# PIC18F27Q10 register map
Vendor: Microchip
Registers are 8-bit, read-write, reset 0x0 unless marked. A register's access mark holds for its fields unless they carry their own. Addresses are absolute, and some are shared; only a register's first bit layout is shown; [hi:lo] are bit positions; {n}, {i} and the like mark numbered series; 'fields as' and 'values as' point back to an identical list.

## wdt_windowed
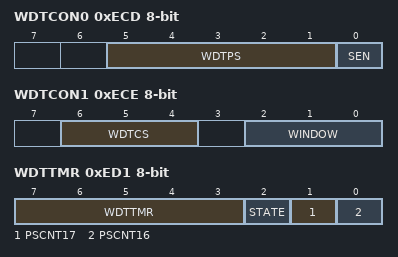
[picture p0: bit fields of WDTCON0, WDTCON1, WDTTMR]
0xECD WDTCON0 reset not defined — (power-on value --qqqqq0)
  [5:1] WDTPS, [0] SEN
0xECE WDTCON1 reset not defined — (power-on value -qqq-qqq)
  [6:4] WDTCS, [2:0] WINDOW
0xECF WDTPSL ro
  [7:0] PSCNT
0xED0 WDTPSH ro
  [7:0] PSCNT
0xED1 WDTTMR ro reset not defined — (power-on value xxxxx000)
  [7:3] WDTTMR, [2] STATE, [1] PSCNT17, [0] PSCNT16

## DOS_02264_pmd_mid8_v1_KFAE
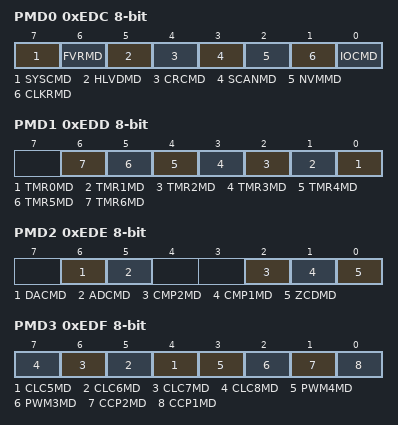
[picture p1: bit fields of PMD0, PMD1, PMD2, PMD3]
0xEDC PMD0 reset not defined — (power-on value 00x00000)
  [7] SYSCMD, [6] FVRMD, [5] HLVDMD, [4] CRCMD, [3] SCANMD, [2] NVMMD, [1] CLKRMD, [0] IOCMD
0xEDD PMD1
  [n] TMR{n}MD (n=0..6)
0xEDE PMD2
  [6] DACMD, [5] ADCMD, [2] CMP2MD, [1] CMP1MD, [0] ZCDMD
0xEDF PMD3
  [n-1] CLC{n}MD (n=5..8), [3] PWM4MD, [2] PWM3MD, [1] CCP2MD, [0] CCP1MD
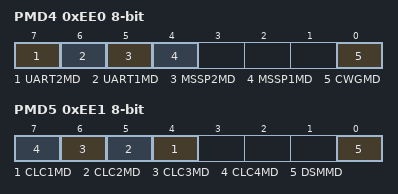
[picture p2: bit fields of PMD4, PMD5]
0xEE0 PMD4
  [7] UART2MD, [6] UART1MD, [5] MSSP2MD, [4] MSSP1MD, [0] CWGMD
0xEE1 PMD5
  [n+3] CLC{n}MD (n=1..4), [0] DSMMD

## DOS_xxxxx_pps_mid_v2_output_xxK40_8bit
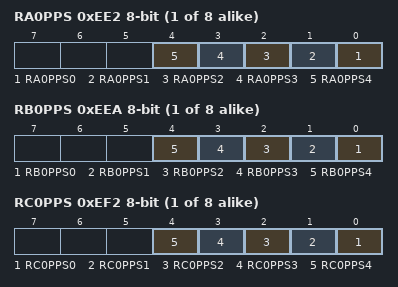
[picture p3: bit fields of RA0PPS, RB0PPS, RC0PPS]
{0xEE2+i} RA{i}PPS (i=0..7)
  [n] RA{i}PPS{n} (n=0..4)
{0xEEA+i} RB{i}PPS (i=0..7)
  [n] RB{i}PPS{n} (n=0..4)
{0xEF2+i} RC{i}PPS (i=0..7)
  [n] RC{i}PPS{n} (n=0..4)

## IOC___Port_Control
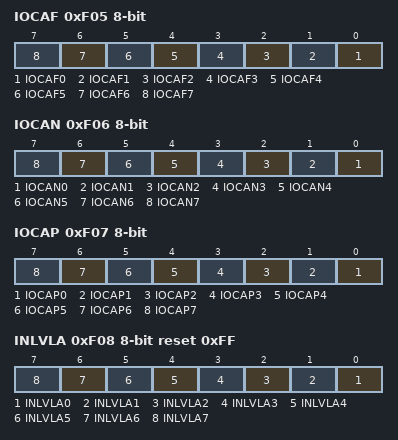
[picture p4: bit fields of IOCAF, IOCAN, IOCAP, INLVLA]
0xF05 IOCAF
  [n] IOCAF{n} (n=0..7)
0xF06 IOCAN
  [n] IOCAN{n} (n=0..7)
0xF07 IOCAP
  [n] IOCAP{n} (n=0..7)
0xF08 INLVLA reset 0xFF
  [n] INLVLA{n} (n=0..7)
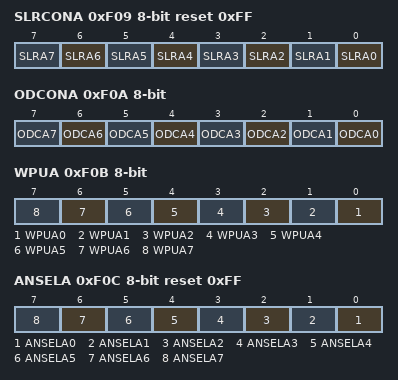
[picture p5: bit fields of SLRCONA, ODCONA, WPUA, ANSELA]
0xF09 SLRCONA reset 0xFF
  [n] SLRA{n} (n=0..7)
0xF0A ODCONA
  [n] ODCA{n} (n=0..7)
0xF0B WPUA
  [n] WPUA{n} (n=0..7)
0xF0C ANSELA reset 0xFF
  [n] ANSELA{n} (n=0..7)
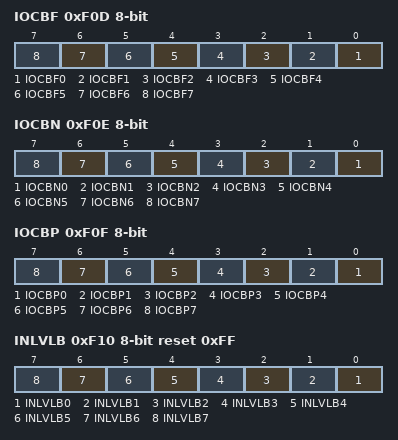
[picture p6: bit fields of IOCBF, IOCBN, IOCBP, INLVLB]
0xF0D IOCBF
  [n] IOCBF{n} (n=0..7)
0xF0E IOCBN
  [n] IOCBN{n} (n=0..7)
0xF0F IOCBP
  [n] IOCBP{n} (n=0..7)
0xF10 INLVLB reset 0xFF
  [n] INLVLB{n} (n=0..7)
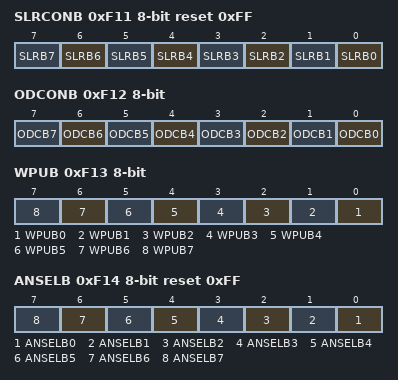
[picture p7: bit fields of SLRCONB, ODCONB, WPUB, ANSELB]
0xF11 SLRCONB reset 0xFF
  [n] SLRB{n} (n=0..7)
0xF12 ODCONB
  [n] ODCB{n} (n=0..7)
0xF13 WPUB
  [n] WPUB{n} (n=0..7)
0xF14 ANSELB reset 0xFF
  [n] ANSELB{n} (n=0..7)
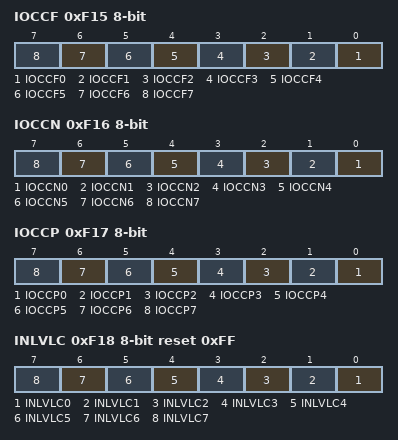
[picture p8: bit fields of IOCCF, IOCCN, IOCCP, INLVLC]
0xF15 IOCCF
  [n] IOCCF{n} (n=0..7)
0xF16 IOCCN
  [n] IOCCN{n} (n=0..7)
0xF17 IOCCP
  [n] IOCCP{n} (n=0..7)
0xF18 INLVLC reset 0xFF
  [n] INLVLC{n} (n=0..7)
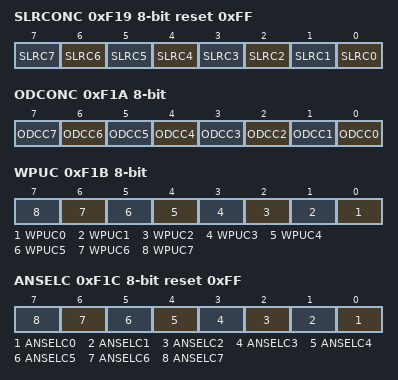
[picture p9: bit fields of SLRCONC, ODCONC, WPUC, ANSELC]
0xF19 SLRCONC reset 0xFF
  [n] SLRC{n} (n=0..7)
0xF1A ODCONC
  [n] ODCC{n} (n=0..7)
0xF1B WPUC
  [n] WPUC{n} (n=0..7)
0xF1C ANSELC reset 0xFF
  [n] ANSELC{n} (n=0..7)
0xF22 IOCEF
  [3] IOCEF3
0xF23 IOCEN
  [3] IOCEN3
0xF24 IOCEP
  [3] IOCEP3
0xF25 INLVLE reset 0x8
  [3] INLVLE3
0xF28 WPUE
  [3] WPUE3

## lvd_ctrl
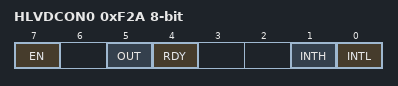
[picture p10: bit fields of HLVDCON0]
0xF2A HLVDCON0 reset not defined — (power-on value 0-xx--00)
  [7] EN, [5] OUT ro, [4] RDY ro, [1] INTH, [0] INTL
0xF2B HLVDCON1
  [3:0] SEL

## amp_fvr_ts_ctrl
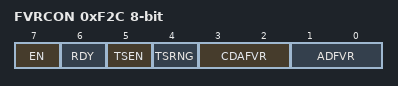
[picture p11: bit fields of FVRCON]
0xF2C FVRCON reset not defined — (power-on value xx000000)
  [7] EN — Zero-Cross Detect Software Enable bit
  [6] RDY ro
  [5] TSEN — Zero-Cross Detect Data Output
  [4] TSRNG — Zero-Cross Detect Polarity bit
  [3:2] CDAFVR
  [1:0] ADFVR — Zero-Cross Detect Positive-going Edge Interrupt Enable

## cmp_zxover_ctrl
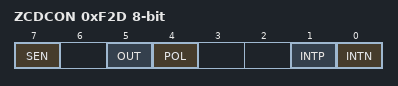
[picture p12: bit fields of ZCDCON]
0xF2D ZCDCON reset not defined — ZERO CROSS DETECT CONTROL REGISTER (power-on value 0-x0--00)
  [7] SEN — Zero-Cross Detect Software Enable bit
  [5] OUT ro — Zero-Cross Detect Data Output
  [4] POL — Zero-Cross Detect Polarity bit
  [1] INTP — Zero-Cross Detect Positive-going Edge Interrupt Enable
  [0] INTN — Zero-Cross Detect Negative-going Edge Interrupt Enable

## dac_nbit_ctrl
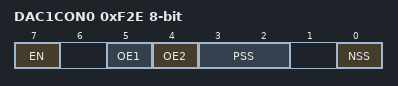
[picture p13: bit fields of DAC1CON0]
0xF2E DAC1CON0
  [7] EN, [5] OE1, [4] OE2, [3:2] PSS, [0] NSS
0xF2F DAC1CON1 reset not defined — (power-on value ---xxxxx)
  [4:0] DAC1R

## cmp_rr_ctrl
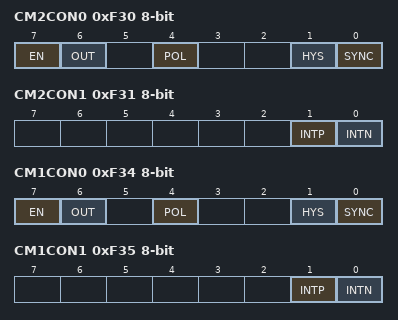
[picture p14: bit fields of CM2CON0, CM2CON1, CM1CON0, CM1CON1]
0xF30 CM2CON0 — COMPARATOR CONTROL REGISTER 0
  [7] EN — Comparator Enable bit
  [6] OUT ro — Comparator Output bit
  [4] POL — Comparator Output Polarity Select bit
  [1] HYS — Comparator Hysteresis Enable bit
  [0] SYNC — Comparator Output Synchronous Mode bit
0xF31 CM2CON1 — COMPARATOR CONTROL REGISTER 1
  [1] INTP — Comparator Interrupt on Positive going edge Enable bits
  [0] INTN — Comparator Interrupt on Negative going edge Enable bits
0xF32 CM2NCH — COMPARATOR INVERTING CHANNEL SELECT REGISTER
  [2:0] NCH — Comparator Inverting Input Channel Select bits
0xF33 CM2PCH — COMPARATOR NON-INVERTING CHANNEL SELECT REGISTER
  [2:0] PCH — Comparator Non-Inverting Input Channel Select bits
0xF34 CM1CON0 — COMPARATOR CONTROL REGISTER 0
  fields as CM2CON0
0xF35 CM1CON1 — COMPARATOR CONTROL REGISTER 1
  fields as CM2CON1
0xF36 CM1NCH — COMPARATOR INVERTING CHANNEL SELECT REGISTER
  [2:0] NCH — Comparator Inverting Input Channel Select bits
0xF37 CM1PCH — COMPARATOR NON-INVERTING CHANNEL SELECT REGISTER
  [2:0] PCH — Comparator Non-Inverting Input Channel Select bits
